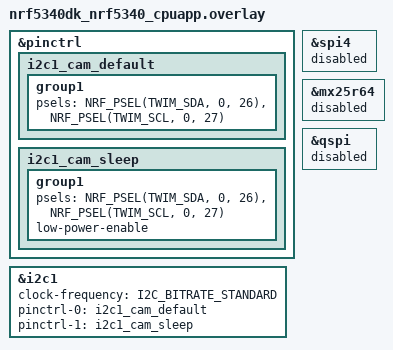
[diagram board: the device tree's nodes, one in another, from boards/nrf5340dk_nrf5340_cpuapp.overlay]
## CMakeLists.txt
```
cmake_minimum_required(VERSION 3.20.0)

find_package(Zephyr REQUIRED HINTS $ENV{ZEPHYR_BASE})
project(vuebuds_nrf5340)

# Compile-time choices, same names and values as fw/Makefile. tools/dk5340.py passes them as
# -Dfw_nrf5340_<var>=... (sysbuild hands image-prefixed variables to this image only).
#   CAM_MODE          QVGA (default), QQVGA or VGA (HM0360 only)
#   CAM_TEST_PATTERN  OFF (default), COLOR_BAR or WALKING_1
#   CAM_APP           STREAM (default) or MONITOR
#   EXTRA_DEFINES     extra defines, ';'-separated (like fw/'s CFLAGS=-DXXX)
#   CAM_BOARD         DK (default) or V3_L / V3_R: the V3 board (balsamic3, hub #83), with
#                     boards/balsamic3.overlay passed as EXTRA_DTC_OVERLAY_FILE (dk5340.py)
foreach(var CAM_MODE CAM_TEST_PATTERN CAM_APP EXTRA_DEFINES CAM_BOARD)
  zephyr_get(${var} SYSBUILD LOCAL)
endforeach()
if(NOT CAM_MODE)
  set(CAM_MODE QVGA)
endif()
if(NOT CAM_TEST_PATTERN)
  set(CAM_TEST_PATTERN OFF)
endif()
if(NOT CAM_APP)
  set(CAM_APP STREAM)
endif()
if(NOT CAM_BOARD)
  set(CAM_BOARD DK)
endif()
message(STATUS "vuebuds: CAM_MODE=${CAM_MODE} CAM_TEST_PATTERN=${CAM_TEST_PATTERN} CAM_APP=${CAM_APP} CAM_BOARD=${CAM_BOARD} EXTRA_DEFINES=${EXTRA_DEFINES}")

set(FW ${CMAKE_CURRENT_SOURCE_DIR}/../fw)

target_compile_definitions(app PRIVATE
  CAMERA_MODE=CAMERA_MODE_${CAM_MODE}
  CAM_MODE_${CAM_MODE}  # for #ifdef: CAMERA_MODE_* are enum values, invisible to #if
  CAMERA_TEST_PATTERN=CAMERA_TEST_PATTERN_${CAM_TEST_PATTERN}
  ${EXTRA_DEFINES}
)
if(CAM_BOARD MATCHES "^V3_([LR])$")
  target_compile_definitions(app PRIVATE BOARD_V3 BOARD_SIDE="${CMAKE_MATCH_1}")
elseif(NOT CAM_BOARD STREQUAL "DK")
  message(FATAL_ERROR "CAM_BOARD must be DK, V3_L or V3_R, not ${CAM_BOARD}")
endif()
if(CAM_APP STREQUAL "MONITOR")
  target_compile_definitions(app PRIVATE CAMERA_APP_MONITOR)
endif()

# Sensor drivers and register tables are shared with fw/ (not copied). They see the
# nRF5 SDK headers they include (i2c.h, timers.h, nrf_log.h, ...) through src/compat.
target_include_directories(app PRIVATE
  src
  src/compat
  src/capture
  ${FW}/sensors
  ${FW}/sensors/hm01b0/include
  ${FW}/sensors/hm0360/include
)
target_sources(app PRIVATE
  ${FW}/sensors/camera_sensor.c
  ${FW}/sensors/hm01b0/hm01b0_mode_info.c
  ${FW}/sensors/hm01b0/hm01b0_modes.c
  ${FW}/sensors/hm01b0/hm01b0_reg.c
  ${FW}/sensors/hm01b0/hm01b0_sensor.c
  ${FW}/sensors/hm0360/hm0360_mode_info.c
  ${FW}/sensors/hm0360/hm0360_modes.c
  ${FW}/sensors/hm0360/hm0360_reg.c
  ${FW}/sensors/hm0360/hm0360_sensor.c
)
file(GLOB APP_SOURCES src/*.c src/compat/*.c src/capture/*.c)
target_sources(app PRIVATE ${APP_SOURCES})

# JPEG / PNG encoders (lib/README.md): src/codec_jpeg.c / codec_png.c include the .inl files;
# PNGenc's zlib subset is built here, warnings off for this third-party code.
target_include_directories(app PRIVATE lib/jpegenc lib/pngenc)
set(ZLIB_SOURCES lib/pngenc/adler32.c lib/pngenc/crc32.c lib/pngenc/deflate.c lib/pngenc/trees.c lib/pngenc/zutil.c)
target_sources(app PRIVATE ${ZLIB_SOURCES})
# -O2 (Zephyr builds -Os): measured faster encodes, see DEVLOG 10-11.
set_source_files_properties(${ZLIB_SOURCES} src/codec_jpeg.c src/codec_png.c PROPERTIES COMPILE_OPTIONS "-w;-O2")
```

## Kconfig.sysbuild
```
source "share/sysbuild/Kconfig"

# Network core runs Nordic's ipc_radio image as the BLE controller (HCI over IPC).
config NRF_DEFAULT_IPC_RADIO
	default y

config NETCORE_IPC_RADIO_BT_HCI_IPC
	default y
```

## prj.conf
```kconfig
# Logs: printk to RTT (same channel as fw/'s NRF_LOG RTT backend), no UART console.
CONFIG_CONSOLE=y
CONFIG_PRINTK=y
CONFIG_USE_SEGGER_RTT=y
CONFIG_RTT_CONSOLE=y
CONFIG_UART_CONSOLE=n
CONFIG_SERIAL=n
CONFIG_SEGGER_RTT_BUFFER_SIZE_UP=4096

CONFIG_GPIO=y
CONFIG_I2C=y

CONFIG_MAIN_STACK_SIZE=4096
CONFIG_SYSTEM_WORKQUEUE_STACK_SIZE=2048

# BLE peripheral "mustard": same service, characteristics and packet format as fw/
# (host/protocol.py). The controller runs on the network core (sysbuild/ipc_radio).
CONFIG_BT=y
CONFIG_BT_PERIPHERAL=y
CONFIG_BT_GATT_CLIENT=y
CONFIG_BT_DEVICE_NAME="mustard"
CONFIG_BT_MAX_CONN=1
# Data length 251 like fw/ (NRF_SDH_BLE_GAP_DATA_LENGTH). ATT MTU 498 (fw/: 247; user 10-11):
# one 495-byte notification fills exactly two 251-byte link-layer packets (498 + 4 L2CAP = 502),
# half the notifications for the receiver to process (bridge: 1.38 -> 1.56 fps QVGA).
# The MTU is the smaller of the two sides' (Windows / the bridge accept 498).
CONFIG_BT_L2CAP_TX_MTU=498
CONFIG_BT_BUF_ACL_RX_SIZE=502
CONFIG_BT_BUF_ACL_TX_SIZE=251
CONFIG_BT_BUF_ACL_TX_COUNT=10
CONFIG_BT_BUF_EVT_RX_COUNT=11
CONFIG_BT_ATT_TX_COUNT=10
CONFIG_BT_CONN_TX_MAX=10
CONFIG_BT_USER_DATA_LEN_UPDATE=y
# fw/'s nrf_ble_gatt starts the data length update (251) after connecting.
CONFIG_BT_AUTO_DATA_LEN_UPDATE=y
# fw/ only answers PHY update requests (BLE_GAP_PHY_AUTO), it does not start one.
CONFIG_BT_AUTO_PHY_UPDATE=n
CONFIG_BT_USER_PHY_UPDATE=y
# Preferred connection parameters 7.5-15 ms, latency 0, timeout 4 s (fw/main.h), requested
# 5 s after connecting like FIRST_CONN_PARAMS_UPDATE_DELAY.
CONFIG_BT_GAP_AUTO_UPDATE_CONN_PARAMS=y
CONFIG_BT_PERIPHERAL_PREF_MIN_INT=6
CONFIG_BT_PERIPHERAL_PREF_MAX_INT=12
CONFIG_BT_PERIPHERAL_PREF_LATENCY=0
CONFIG_BT_PERIPHERAL_PREF_TIMEOUT=400
CONFIG_BT_CONN_PARAM_UPDATE_TIMEOUT=5000
CONFIG_REBOOT=y
# Time sync (src/timesync.c): connection anchor point reports from the controller (HCI VS event).
CONFIG_BT_HCI_VS_EVT_USER=y

# The frame pool takes all RAM after the image (src/capture/frame_pool.c); libc malloc would
# otherwise claim the same region as its arena. Nothing calls malloc.
CONFIG_COMMON_LIBC_MALLOC=n

# PSRAM on QSPI (src/psram.c): the nrfx driver only, no Zephyr flash driver.
CONFIG_NRFX_QSPI=y

# CRC32 for the PSRAM ring read-back check (src/ring.c, hub #26)
CONFIG_CRC=y
```

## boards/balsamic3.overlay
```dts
/*
 * balsamic3 (V3 board, hub #83): added on top of nrf5340dk_nrf5340_cpuapp.overlay by
 * tools/dk5340.py --board V3L / V3R (-Dfw_nrf5340_EXTRA_DTC_OVERLAY_FILE). Pins are the same as
 * on the DK (kicad-agent-flow boards/balsamic3/board.yaml, hub INTERFACES G): camera, I2C on
 * P0.26 / P0.27 (PMIC MAX77650 at 0x48, camera at 0x24) and the PSRAM on the QSPI pins. Only the
 * ISP2053 module differs, as in fw_v3_test/boards (verified on V3 2026-10):
 * - 32.768 kHz crystal: load capacitors are inside the module; ISP2053 DS R11 p.8 says
 *   XOSC32KI.INTCAP must select "External" (the DK uses internal 7 pF).
 * - Supply: VDD and VDDH tied to +1V8 (normal mode, DCCH open), so the VDDH regulator is unused;
 *   the module integrates the DC/DC inductors.
 * No buttons or LEDs are used (the firmware never used the DK's either). FSIN is not connected
 * on V3 (P1.11 free); the firmware does not drive it outside HW_TEST.
 */
&lfxo {
	load-capacitors = "external";
	/delete-property/ load-capacitance-picofarad;
};

&vregh {
	status = "disabled";
};
```

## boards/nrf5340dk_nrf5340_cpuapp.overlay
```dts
/*
 * Camera wiring on the nRF5340 DK (Obsidian note "nrf5340迁移" §2, src/pins.h).
 * Camera I2C on TWIM1 at P0.26 SDA / P0.27 SCL, 100 kHz like fw/. The DK's default
 * i2c1 pins (P1.02 / P1.03) are the camera PCLK / D0 here.
 * SPIS2 (camera data), TIMER0-2, EGU0 and DPPI channels 16-24 are used by the
 * application at register level (src/capture), so their nodes stay disabled.
 */
&pinctrl {
	i2c1_cam_default: i2c1_cam_default {
		group1 {
			psels = <NRF_PSEL(TWIM_SDA, 0, 26)>,
				<NRF_PSEL(TWIM_SCL, 0, 27)>;
		};
	};

	i2c1_cam_sleep: i2c1_cam_sleep {
		group1 {
			psels = <NRF_PSEL(TWIM_SDA, 0, 26)>,
				<NRF_PSEL(TWIM_SCL, 0, 27)>;
			low-power-enable;
		};
	};
};

&i2c1 {
	status = "okay";
	clock-frequency = <I2C_BITRATE_STANDARD>;
	pinctrl-0 = <&i2c1_cam_default>;
	pinctrl-1 = <&i2c1_cam_sleep>;
	pinctrl-names = "default", "sleep";
};

/* Arduino SPI (P1.13-P1.15): not used. */
&spi4 {
	status = "disabled";
};

/*
 * QSPI (P0.13-P0.18): the PSRAM (src/psram.c, nrfx_qspi at register level). The onboard
 * MX25R64 flash is cut off on our DKs (SB10-SB15 open, SB20-SB25 shorted), so no flash driver.
 */
&mx25r64 {
	status = "disabled";
};

&qspi {
	status = "disabled";
};
```

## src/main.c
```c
/*
 * nRF5340 DK port of fw/main.c: camera + BLE streaming (CAM_APP=STREAM, the default; it
 * also takes single pictures on 0xB2, snapshot.h) or Monitor (CAM_APP=MONITOR). The main thread runs the same event loop as fw/; it sleeps in
 * eventQueueWait() instead of nrf_pwr_mgmt_run(), and sends a frame in one call
 * (imageSend / bleSendImage return once every packet is queued) instead of polling bleService().
 * The VueBuds board's PMU, IMU, buttons, LEDs and CLI are not ported.
 */
#include <zephyr/kernel.h>
#include <zephyr/sys/reboot.h>
#ifdef CPU_128MHZ
#include <nrfx_clock.h>
#endif

#include "nrf_log.h"
#include "event.h"
#include "camera.h"
#include "monitor.h"
#include "snapshot.h"
#include "ble.h"
#include "image.h"
#include "timesync.h"
#include "ringcmd.h"
#include "i2c.h"
#include "psram.h"
#include "timers.h"
#ifdef BOARD_V3
#include "pmic.h"
#endif

#ifdef CAPTURE_STRESS_US
extern void stressTestStart(void);
#endif

// Stream builds take either a continuous stream (0xB1) or single / timed pictures (0xB2 / 0xB8) per boot.
static bool streaming;

static void processEvent(event_t event)
{
  switch (event) {
    case EVENT_BLE_DATA_STREAM_START:
      NRF_LOG_RAW_INFO("%08d [ble] stream start\n", systemTimeGetMs());
      break;

    case EVENT_BLE_DATA_STREAM_STOP:
    case EVENT_BLE_DISCONNECTED:
      sys_reboot(SYS_REBOOT_COLD);  // fw/: NVIC_SystemReset()
      break;

    case EVENT_CAMERA_STREAM_START:
#ifdef CAMERA_APP_MONITOR
      NRF_LOG_RAW_INFO("%08d [main] Monitor build: BLE streaming is disabled\n", systemTimeGetMs());
      break;
#endif
      if (snapshotActive() && !snapshotHandOver()) {
        // 0xB1 after 0xB2 / 0xB8 only once those are stopped (0xB8 0) and idle (INTERFACES C2).
        NRF_LOG_RAW_INFO("%08d [main] taking pictures (0xB2 / 0xB8): stream start ignored\n", systemTimeGetMs());
        break;
      }
      streaming = true;
      cameraInit();
      cameraStartStream();
#ifdef CAPTURE_STRESS_US
      stressTestStart();
#endif
      break;

    case EVENT_CAMERA_SNAPSHOT:
#ifdef CAMERA_APP_MONITOR
      NRF_LOG_RAW_INFO("%08d [main] Monitor build: single pictures are disabled\n", systemTimeGetMs());
      break;
#endif
      if (streaming) {
        NRF_LOG_RAW_INFO("%08d [main] streaming (0xB1): picture request ignored\n", systemTimeGetMs());
        break;
      }
      snapshotRequest();
      break;

    case EVENT_CAMERA_CAPTURE_DONE: {
#ifdef CAMERA_APP_MONITOR
      monitorFrameDone();
      break;
#endif
      if (snapshotActive()) {
        snapshotFrameDone();
        break;
      }
      NRF_LOG_RAW_INFO("%08d [cam] EVENT_CAMERA_CAPTURE_DONE\n", systemTimeGetMs());
      camera_frame_t frame;
      if (cameraGetFrame(&frame)) {
        imagePrepare(&frame);
        imageSend(&frame);
      }
      // Sent (or a bad frame, not sent): capture the next one.
      eventQueuePush(EVENT_CAMERA_READY_NEXT_FRAME);
      break;
    }

    case EVENT_CAMERA_READY_NEXT_FRAME:
      NRF_LOG_RAW_INFO("%08d [cam] EVENT_CAMERA_READY_NEXT_FRAME\n", systemTimeGetMs());
      cameraReadyNextFrame();
      break;

#ifdef CAMERA_APP_MONITOR
    case EVENT_MONITOR_START:
      monitorStart();
      break;

    case EVENT_MONITOR_WAKE:
      monitorWake();
      break;

    case EVENT_CAMERA_ASLEEP:
      monitorAsleep();
      break;
#else
    case EVENT_CAMERA_ASLEEP:
      snapshotAsleep();
      break;

    case EVENT_CAMERA_TIMED:
      snapshotTimedTick();
      break;

    case EVENT_CAMERA_RING_DUE:
      snapshotRingDue();
      break;
#endif

    case EVENT_BLE_COMMAND: {
      ble_command_t cmd;
      while (bleNextCommand(&cmd)) {
        if (cmd.data[0] == TIMESYNC_CMD_REFERENCE || cmd.data[0] == TIMESYNC_CMD_SNAPSHOT_AT) {
          uint64_t at;
          bool timed = timesyncCommand(&cmd, &at);
          (void)timed;  // Monitor builds take no pictures
#ifndef CAMERA_APP_MONITOR
          if (cmd.data[0] == TIMESYNC_CMD_SNAPSHOT_AT && !streaming) {
            if (timed) {
              snapshotRequestAt(at);
            } else {
              snapshotRequest();  // no time reference yet: now, like 0xB2
            }
          }
#endif
          continue;
        }
#ifndef CAMERA_APP_MONITOR
        if (cmd.data[0] == SNAPSHOT_CMD_TIMED) {
          if (streaming) {
            NRF_LOG_RAW_INFO("%08d [main] streaming (0xB1): timed capture / ring ignored\n", systemTimeGetMs());
          } else {
            ringcmdCommand(&cmd);  // 0xB8 0 / 1 / 2 (snapshot.h, ringcmd.h)
          }
          continue;
        }
        if (cmd.data[0] == RINGCMD_STATUS || cmd.data[0] == RINGCMD_FETCH) {
          ringcmdCommand(&cmd);  // also after a hand-over to the stream: the frames stay
          continue;
        }
#endif
        imageCommand(&cmd);
#ifndef CAMERA_APP_MONITOR
        if (cmd.data[0] == IMAGE_CMD_SET_EXPOSURE) {
          snapshotExposureChanged();
        } else if (cmd.data[0] == IMAGE_CMD_CODEC_BENCH && !streaming) {
          snapshotRequest();  // the bench picture (while streaming: the next streamed frame)
        }
#endif
      }
      break;
    }

    case EVENT_PSRAM_CHECK:
      psramCheckFinish();
#ifndef CAMERA_APP_MONITOR
      ringcmdInit();
#endif
      break;

    default:
      NRF_LOG_RAW_INFO("%08d [main] unhandled event:%d\n", systemTimeGetMs(), event);
      break;
  }
}

static void psramCheckDue(struct k_timer *t)
{
  eventQueuePush(EVENT_PSRAM_CHECK);
}
static K_TIMER_DEFINE(psramCheckTimer, psramCheckDue, NULL);

int main(void)
{
#ifdef BOARD_V3
  // V3 board (hub #83): camera AVDD from 3.3 V (PMIC power-up default) to 2.8 V before anything
  // else; the camera stays in reset (XSHUTDN pull-down) until then.
  bool pmicOk = pmicInit();
#endif
#ifdef CPU_128MHZ
  // Experiment (10-11): the application core runs at 64 MHz by default (HFCLK / 2); 128 MHz as
  // in nrf/samples/bluetooth/nrf_auraconfig, for the JPEG / PNG encoders.
  int divErr = nrfx_clock_divider_set(NRF_CLOCK_DOMAIN_HFCLK, NRF_CLOCK_HFCLK_DIV_1);
  SystemCoreClockUpdate();
  NRF_LOG_RAW_INFO("[mustard] CPU %u MHz (%d)\n", SystemCoreClock / 1000000, divErr);
#endif
#ifdef BOARD_V3
  NRF_LOG_RAW_INFO("%08d [mustard] booting... (nRF5340, V3 board %s, PMIC %s)\n", systemTimeGetMs(), BOARD_SIDE,
                   pmicOk ? "ok" : "NOT OK");
#else
  NRF_LOG_RAW_INFO("%08d [mustard] booting... (nRF5340)\n", systemTimeGetMs());
#endif
  i2cInit();
#ifdef HW_TEST
  extern void hwTestRun(void);
  hwTestRun();  // hardware check only (src/hw_test.c): no BLE, no camera application
  for (;;) {
    k_sleep(K_FOREVER);
  }
#endif
  // PSRAM boot check (psram.h): write now, read back PSRAM_CHECK_WAIT_MS later without holding
  // up BLE; a picture compressed before then waits for it (image.c).
  psramCheckStart();
  if (psramState() == PSRAM_STATE_WAITING) {
    k_timer_start(&psramCheckTimer, K_MSEC(PSRAM_CHECK_WAIT_MS), K_NO_WAIT);
  } else {
    eventQueuePush(EVENT_PSRAM_CHECK);  // failed at once: set up the ring (in RAM) now
  }
  bleInit();
#ifdef BOARD_V3
  cameraProbe();  // V3 boards start without a camera module (hub #83): say so in the log
#endif
  NRF_LOG_RAW_INFO("%08d [mustard] booted\n", systemTimeGetMs());

#ifdef CAMERA_APP_MONITOR
  eventQueuePush(EVENT_MONITOR_START);
#endif

  for (;;) {
    processEvent(eventQueueWait());
  }
  return 0;
}
```

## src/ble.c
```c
/*
 * BLE peripheral "mustard" on Zephyr, same protocol as fw/ble_manager.c + fw/ble_cus.c:
 *   service 47ea1400-a0e4-554e-5282-0afcd3246970
 *   data    ...1402  notify: [seq, flags, payload...], flags bit0 = start of frame; fw/'s
 *                   start-of-frame payload begins with width, height (uint16 LE each); here
 *                   flags bit1 is set and it begins with ble_frame_header_t (v2, ble.h)
 *   control ...1403  write 0xB1: start the camera stream (read / notify, 1 byte)
 *                    write 0xB2: take one picture (not in fw/; see snapshot.h)
 *                    longer writes (0xB3 ...): commands for the main thread (image.c, ringcmd.c)
 *   data packets with flags bit2 are M2 replies [seq, 0x04, type, ...] (ringcmd.h)
 * Like fw/, turning data notifications off or disconnecting reboots the chip.
 */
#include <string.h>

#include <zephyr/kernel.h>
#include <zephyr/sys/util.h>
#include <zephyr/bluetooth/bluetooth.h>
#include <zephyr/bluetooth/conn.h>
#include <zephyr/bluetooth/gatt.h>
#include <zephyr/bluetooth/uuid.h>

#include "nrf_log.h"
#include "event.h"
#include "timers.h"
#include "ble.h"
#include "timesync.h"

#define ADV_INTERVAL 300  // 187.5 ms in 0.625 ms units, as fw/main.h APP_ADV_INTERVAL
#define PACKET_FLAG_START_OF_FRAME 0x01
#define PACKET_FLAG_HEADER_V2 0x02
#define PACKET_FLAG_REPLY 0x04  // M2 reply packet (R_STATUS ..., ble.h)
#define CMD_STREAM_START 0xB1
#define CMD_STREAM_STOP 0xB0
#define CMD_SNAPSHOT 0xB2
#define NOTIFY_IN_FLIGHT CONFIG_BT_ATT_TX_COUNT
#define NOTIFY_WAIT_MS 2000  // no notification completed for this long: give up the frame

#define UUID_BASE(x) BT_UUID_128_ENCODE(0x47ea0000 | (x), 0xa0e4, 0x554e, 0x5282, 0x0afcd3246970)
static const struct bt_uuid_128 serviceUuid = BT_UUID_INIT_128(UUID_BASE(0x1400));
static const struct bt_uuid_128 dataUuid = BT_UUID_INIT_128(UUID_BASE(0x1402));
static const struct bt_uuid_128 controlUuid = BT_UUID_INIT_128(UUID_BASE(0x1403));

static struct bt_conn *currentConn;
static uint8_t controlValue;
static uint8_t sequenceNumber;
static uint8_t packet[CONFIG_BT_L2CAP_TX_MTU];
K_SEM_DEFINE(notifySlots, NOTIFY_IN_FLIGHT, NOTIFY_IN_FLIGHT);
BUILD_ASSERT(sizeof(ble_frame_header_t) == 22, "frame header v2 is 22 bytes (host/protocol.py HEADER_V2)");
K_MSGQ_DEFINE(commandQueue, sizeof(ble_command_t), 8, 4);
// Data notifications come from the main thread (stream, pictures) and the ring sender thread
// (ringcmd.c): one frame's packets go out back to back, replies between frames (recursive).
K_MUTEX_DEFINE(txLock);

static void dataCccChanged(const struct bt_gatt_attr *attr, uint16_t value)
{
  if (value & BT_GATT_CCC_NOTIFY) {
    eventQueuePush(EVENT_BLE_DATA_STREAM_START);
  } else {
    eventQueuePush(EVENT_BLE_DATA_STREAM_STOP);
  }
}

static ssize_t controlRead(struct bt_conn *conn, const struct bt_gatt_attr *attr, void *buf, uint16_t len,
                           uint16_t offset)
{
  return bt_gatt_attr_read(conn, attr, buf, len, offset, &controlValue, sizeof(controlValue));
}

static ssize_t controlWrite(struct bt_conn *conn, const struct bt_gatt_attr *attr, const void *buf, uint16_t len,
                            uint16_t offset, uint8_t flags)
{
  if (offset != 0 || len < 1 || len > BLE_COMMAND_MAX) {
    return BT_GATT_ERR(BT_ATT_ERR_INVALID_ATTRIBUTE_LEN);
  }
  uint8_t cmd = *(const uint8_t *)buf;
  NRF_LOG_INFO("writing to 1403 0x%02x (%u bytes)", cmd, len);
  if (len > 1 || (cmd != CMD_STREAM_START && cmd != CMD_SNAPSHOT && cmd != CMD_STREAM_STOP)) {
    ble_command_t c = {.len = len};
    memcpy(c.data, buf, len);
    if (k_msgq_put(&commandQueue, &c, K_NO_WAIT) == 0) {
      eventQueuePush(EVENT_BLE_COMMAND);
    }
  } else if (cmd == CMD_STREAM_START) {
    eventQueuePush(EVENT_CAMERA_STREAM_START);
  } else if (cmd == CMD_SNAPSHOT) {
    eventQueuePush(EVENT_CAMERA_SNAPSHOT);
  }
  // 0xB0 (stream stop) did nothing in fw/ either; the audio / timesync commands are not ported.
  return len;
}

static void controlCccChanged(const struct bt_gatt_attr *attr, uint16_t value) {}

BT_GATT_SERVICE_DEFINE(mustardService,
  BT_GATT_PRIMARY_SERVICE(&serviceUuid),
  BT_GATT_CHARACTERISTIC(&dataUuid.uuid, BT_GATT_CHRC_NOTIFY, BT_GATT_PERM_NONE, NULL, NULL, NULL),
  BT_GATT_CCC(dataCccChanged, BT_GATT_PERM_READ | BT_GATT_PERM_WRITE),
  BT_GATT_CHARACTERISTIC(&controlUuid.uuid,
                         BT_GATT_CHRC_READ | BT_GATT_CHRC_WRITE_WITHOUT_RESP | BT_GATT_CHRC_NOTIFY,
                         BT_GATT_PERM_READ | BT_GATT_PERM_WRITE, controlRead, controlWrite, NULL),
  BT_GATT_CCC(controlCccChanged, BT_GATT_PERM_READ | BT_GATT_PERM_WRITE),
);

#define DATA_ATTR (&mustardService.attrs[2])
#define CONTROL_ATTR (&mustardService.attrs[5])

static const struct bt_data advData[] = {
  BT_DATA_BYTES(BT_DATA_FLAGS, (BT_LE_AD_GENERAL | BT_LE_AD_NO_BREDR)),
  BT_DATA(BT_DATA_NAME_COMPLETE, CONFIG_BT_DEVICE_NAME, sizeof(CONFIG_BT_DEVICE_NAME) - 1),
  BT_DATA_BYTES(BT_DATA_UUID128_ALL, UUID_BASE(0x1400)),
};

static void mtuExchanged(struct bt_conn *conn, uint8_t err, struct bt_gatt_exchange_params *params)
{
  NRF_LOG_INFO("ATT MTU exchange %s, MTU %u", err ? "failed" : "done", bt_gatt_get_mtu(conn));
}
static struct bt_gatt_exchange_params mtuParams = {.func = mtuExchanged};

static void connected(struct bt_conn *conn, uint8_t err)
{
  if (err) {
    NRF_LOG_RAW_INFO("%08d [ble] connection failed (0x%02x)\n", systemTimeGetMs(), err);
    return;
  }
  currentConn = bt_conn_ref(conn);
  NRF_LOG_RAW_INFO("%08d [ble] connected\n", systemTimeGetMs());
  bt_gatt_exchange_mtu(conn, &mtuParams);  // like nrf_ble_gatt: ask for the largest MTU (498, prj.conf)
}

static void disconnected(struct bt_conn *conn, uint8_t reason)
{
  NRF_LOG_RAW_INFO("%08d [ble] disconnected (0x%02x)\n", systemTimeGetMs(), reason);
  if (currentConn) {
    bt_conn_unref(currentConn);
    currentConn = NULL;
  }
  eventQueuePush(EVENT_BLE_DISCONNECTED);
}

static void controlNotify(struct k_work *work)
{
  struct bt_conn *conn = currentConn;
  if (conn && bt_gatt_is_subscribed(conn, CONTROL_ATTR, BT_GATT_CCC_NOTIFY)) {
    bt_gatt_notify(conn, CONTROL_ATTR, &controlValue, sizeof(controlValue));
  }
}
static K_WORK_DEFINE(controlNotifyWork, controlNotify);

static void paramsUpdated(struct bt_conn *conn, uint16_t interval, uint16_t latency, uint16_t timeout)
{
  // Same text as fw/ (min, max in ms; host/ble_bench.py parses it). Zephyr reports the one in use.
  NRF_LOG_INFO("Connection interval updated: %d, %d", (5 * interval) / 4, (5 * interval) / 4);
  // fw/ writes 0xFF to the control characteristic here (notified if enabled). Notified from
  // the system work queue: this callback runs on the BT RX thread, which must not block on a
  // TX buffer while a frame fills the queue.
  controlValue = 0xFF;
  k_work_submit(&controlNotifyWork);
}

static void dataLenUpdated(struct bt_conn *conn, struct bt_conn_le_data_len_info *info)
{
  NRF_LOG_INFO("Data length updated to %u bytes.", info->tx_max_len);
}

static void phyUpdated(struct bt_conn *conn, struct bt_conn_le_phy_info *info)
{
  NRF_LOG_INFO("PHY updated: tx %u, rx %u", info->tx_phy, info->rx_phy);
}

BT_CONN_CB_DEFINE(connCallbacks) = {
  .connected = connected,
  .disconnected = disconnected,
  .le_param_updated = paramsUpdated,
  .le_data_len_updated = dataLenUpdated,
  .le_phy_updated = phyUpdated,
};

void bleInit(void)
{
  int err = bt_enable(NULL);
  if (err) {
    NRF_LOG_RAW_INFO("[ble] bt_enable failed (%d)\n", err);
    return;
  }
  timesyncBleReady();
  err = bt_le_adv_start(BT_LE_ADV_PARAM(BT_LE_ADV_OPT_CONN, ADV_INTERVAL, ADV_INTERVAL, NULL), advData,
                        ARRAY_SIZE(advData), NULL, 0);
  if (err) {
    NRF_LOG_RAW_INFO("[ble] advertising failed (%d)\n", err);
    return;
  }
  bt_addr_le_t addr;
  size_t count = 1;
  bt_id_get(&addr, &count);
  char str[BT_ADDR_LE_STR_LEN];
  bt_addr_le_to_str(&addr, str, sizeof(str));
  NRF_LOG_RAW_INFO("%08d [ble] address -> %s\n", systemTimeGetMs(), str);
  NRF_LOG_RAW_INFO("%08d [ble] advertising\n", systemTimeGetMs());
}

static bool sendImage(const ble_frame_header_t *header, ble_reader_t read, void *ctx);

static void notifyDone(struct bt_conn *conn, void *user_data)
{
  k_sem_give(&notifySlots);
}

// Queue one packet; waits while NOTIFY_IN_FLIGHT notifications are in the stack.
static bool sendPacket(uint16_t length)
{
  if (k_sem_take(&notifySlots, K_MSEC(NOTIFY_WAIT_MS)) != 0) {
    NRF_LOG_RAW_INFO("%08d [ble] no notification completed in %d ms, frame dropped\n", systemTimeGetMs(),
                     NOTIFY_WAIT_MS);
    return false;
  }
  if (currentConn == NULL) {
    k_sem_give(&notifySlots);
    return false;
  }
  struct bt_gatt_notify_params params = {
    .attr = DATA_ATTR,
    .data = packet,
    .len = length,
    .func = notifyDone,
  };
  int err = bt_gatt_notify_cb(currentConn, &params);
  if (err) {
    k_sem_give(&notifySlots);
    NRF_LOG_ERROR("ble transmit failed: %d", err);
    return false;
  }
  return true;
}

bool bleNextCommand(ble_command_t *cmd)
{
  return k_msgq_get(&commandQueue, cmd, K_NO_WAIT) == 0;
}

void bleLock(void)
{
  k_mutex_lock(&txLock, K_FOREVER);
}

void bleUnlock(void)
{
  k_mutex_unlock(&txLock);
}

bool bleSendReply(uint8_t type, const void *data, uint16_t len)
{
  bleLock();
  bool ok = false;
  if (currentConn != NULL && 3u + len <= MIN(bt_gatt_get_mtu(currentConn) - 3, sizeof(packet))) {
    packet[0] = sequenceNumber;
    packet[1] = PACKET_FLAG_REPLY;
    packet[2] = type;
    memcpy(&packet[3], data, len);
    ok = sendPacket(3 + len);
    if (ok) {
      sequenceNumber++;
    }
  }
  bleUnlock();
  return ok;
}

bool bleSendImage(const ble_frame_header_t *header, ble_reader_t read, void *ctx)
{
  bleLock();
  bool ok = sendImage(header, read, ctx);
  bleUnlock();
  return ok;
}

static bool sendImage(const ble_frame_header_t *header, ble_reader_t read, void *ctx)
{
  if (currentConn == NULL) {
    return false;
  }
  uint16_t maxPayload = MIN(bt_gatt_get_mtu(currentConn) - 3, sizeof(packet));
  bool startOfFrame = true;
  uint32_t offset = 0;

  while (startOfFrame || offset < header->length) {
    uint16_t length = 0;
    packet[length++] = sequenceNumber;
    packet[length++] = startOfFrame ? (PACKET_FLAG_START_OF_FRAME | PACKET_FLAG_HEADER_V2) : 0;
    if (startOfFrame) {
      memcpy(&packet[length], header, sizeof(*header));
      length += sizeof(*header);
    }
    while (length < maxPayload && offset < header->length) {
      size_t n = read(ctx, offset, &packet[length], MIN(maxPayload - length, header->length - offset));
      if (n == 0) {
        NRF_LOG_RAW_INFO("%08d [ble] image source failed at byte %u, frame dropped\n", systemTimeGetMs(), offset);
        return false;
      }
      length += n;
      offset += n;
    }
    if (!sendPacket(length)) {
      return false;  // disconnected (EVENT_BLE_DISCONNECTED follows) or stalled
    }
    startOfFrame = false;
    sequenceNumber++;
  }
  return true;
}
```

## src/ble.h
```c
/* BLE peripheral, same protocol as fw/ble_manager.c + ble_cus.c (see host/protocol.py). */
#ifndef BLE_H_
#define BLE_H_

#include <stdbool.h>
#include <stddef.h>
#include <stdint.h>

/*
 * Frame header v2 (2026-10-11, host/protocol.py): the start-of-frame packet has flags bit1 set
 * and its payload starts with this header instead of v1's width, height. Little endian.
 */
#define BLE_FORMAT_RAW  0  // 8-bit gray, width x height
#define BLE_FORMAT_PNG  1
#define BLE_FORMAT_JPEG 2

#define BLE_HEADER_COMMON_CLOCK    0x01  // capture_us is on the bridge's common clock (time sync)
#define BLE_HEADER_MANUAL_EXPOSURE 0x02
#define BLE_HEADER_SKIPPED         0x04  // 0xB8: at least one period was skipped before this picture
#define BLE_HEADER_FROM_RING       0x08  // M2: sent out of the ring buffer (after an R_FRAME reply)
#define BLE_HEADER_TIMED           0x10  // 0xB8: taken by the timed capture (not a 0xB2 request)

typedef struct __packed {
  uint16_t width;
  uint16_t height;
  uint8_t format;         // BLE_FORMAT_*
  uint8_t quality;        // JPEG quality, else 0
  uint32_t length;        // image bytes after the header (raw: width x height)
  uint32_t capture_us;    // FVLD rise of this frame (board clock unless BLE_HEADER_COMMON_CLOCK)
  uint16_t frame_id;      // frames sent since boot
  uint16_t integration;   // exposure registers read after the frame: 0x0202 / 0x0203 (rows)
  uint8_t analog_gain;    // 0x0205
  uint16_t digital_gain;  // 0x020E << 8 | 0x020F
  uint8_t flags;          // BLE_HEADER_*
} ble_frame_header_t;

/* Copies image bytes [offset, offset + n) to dst; returns the bytes copied (0: source failed). */
typedef size_t (*ble_reader_t)(void *ctx, uint32_t offset, uint8_t *dst, size_t n);

/* Multi-byte control commands (0xB3 ...), queued for the main thread (EVENT_BLE_COMMAND). */
#define BLE_COMMAND_MAX 24  // 0xB7: 1 + 8 + 2 + 8 bytes
typedef struct {
  uint8_t len;
  uint8_t data[BLE_COMMAND_MAX];
} ble_command_t;

void bleInit(void);  // starts advertising
// Sends header + header->length bytes from read() and returns when every packet is queued.
bool bleSendImage(const ble_frame_header_t *header, ble_reader_t read, void *ctx);
bool bleNextCommand(ble_command_t *cmd);  // false when the queue is empty
/* M2 reply packet [seq, flags 0x04, type, data...] (ringcmd.h); sent between frames. */
bool bleSendReply(uint8_t type, const void *data, uint16_t len);
/* Hold the data channel across several sends (an R_FRAME reply and its frame); recursive. */
void bleLock(void);
void bleUnlock(void);

#endif
```

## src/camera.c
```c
/*
 * nRF5340 port of fw/camera.c. Same flow and constants; app_timer -> k_timer, and
 * cameraDeInit / cameraEnableStandbyMode (power-off and button paths of the VueBuds board,
 * unused on the DK) are not ported.
 */
#include <stdbool.h>
#include <stdint.h>

#include <zephyr/kernel.h>

#include "nrf_log.h"
#include "nrf_delay.h"
#include "event.h"
#include "camera_sensor.h"
#include "capture.h"
#include "camera.h"
#include "pins.h"
#include "timers.h"
#include "i2c.h"
#include "timesync.h"

// Mode and test pattern are compile-time choices (no runtime switching).
#ifndef CAMERA_MODE
#define CAMERA_MODE CAMERA_MODE_QVGA
#endif
#ifndef CAMERA_TEST_PATTERN
#define CAMERA_TEST_PATTERN CAMERA_TEST_PATTERN_OFF
#endif

#define CAMERA_POR_DELAY_MS 100
#define CAMERA_XSHUTDOWN_LOW_MS 10
// Datasheet table 6.2: >= 200 us from reset release to XSLEEP, >= 10 us to the first I2C command.
// Measured: the ID reads back right away; detection polls anyway.
#define CAMERA_BOOT_DELAY_MS 1
#define CAMERA_DETECT_TIMEOUT_MS 1000
#define CAMERA_XSLEEP_SETTLE_US 100  // >= 10 us from XSLEEP high to I2C (datasheet table 6.2)
// Longest wait for a frame boundary. Right after a capture it is 36 blank lines away
// (QQVGA / QVGA 376 us lines: 13.5 ms; VGA 768 us lines: 27.6 ms); requested at another
// time it is up to two frames away (QVGA 2 x 103.8 ms, VGA 2 x 396 ms).
// After-frame timeout: fw/ waits 30 ms. A frame in which the HM0360's AE changed the gain
// has no FVLD low gap at its end at all (measured 10-07: 30 of 30 gain changes, 0 of 28
// unchanged frames), so that wait was always spent in full. 16 ms is just past the 13.5 ms
// boundary; XSLEEP low then does not delay the next wake (user choice B, 10-07).
#ifdef CAM_MODE_VGA  // from CMakeLists (CAMERA_MODE is an enum value, invisible to #if)
#define CAMERA_SLEEP_AFTER_FRAME_TIMEOUT_MS 30
#define CAMERA_SLEEP_ANYTIME_TIMEOUT_MS 850
#else
#define CAMERA_SLEEP_AFTER_FRAME_TIMEOUT_MS 16
#define CAMERA_SLEEP_ANYTIME_TIMEOUT_MS 250
#endif

static void applyPendingExposure(void);  // set before the sensor started (cameraSetExposure)

static bool cameraInitialized = false;
static uint8_t m_state = CAMERA_STATE_UNCHECKED;  // cameraState()
static const camera_sensor_t *sensor = NULL;
static camera_mode_info_t modeInfo;

/*
 * Reset the HM0360 through XSHUTDOWN with MCLK already running, so it always starts
 * from a clean state (it does not answer I2C if it powered up without MCLK), and keep
 * XSLEEP high. Both pins are unconnected on HM01B0 boards, where this does nothing.
 */
static void cameraHardwareReset(void)
{
  nrf_gpio_cfg_output(CAM_XSLEEP);
  nrf_gpio_pin_set(CAM_XSLEEP);
  nrf_gpio_cfg_output(CAM_XSHUTDOWN);
  nrf_gpio_pin_clear(CAM_XSHUTDOWN);
  delayMs(CAMERA_XSHUTDOWN_LOW_MS);
  nrf_gpio_pin_set(CAM_XSHUTDOWN);
  delayMs(CAMERA_BOOT_DELAY_MS);
}

void cameraInit(void)
{
  if (cameraInitialized) {
    NRF_LOG_INFO("[camera] already initialized, skipping");
    return;
  }

  // The sensor runs from our MCLK, including its I2C slave, so start it first.
  capture_mclk_init();
  delayMs(CAMERA_POR_DELAY_MS);
  cameraHardwareReset();

  if (camera_sensor_detect(&sensor, CAMERA_DETECT_TIMEOUT_MS) != NRF_SUCCESS) {
    m_state = CAMERA_STATE_MISSING;
    capture_mclk_enable(false);
    return;
  }
  m_state = CAMERA_STATE_PRESENT;

  if (sensor->get_mode_info(CAMERA_MODE, &modeInfo) != NRF_SUCCESS) {
    // e.g. VGA on an HM01B0 (no such mode): leave the camera off.
    NRF_LOG_RAW_INFO("[camera] %s has no %s mode, camera not started\n", sensor->name,
                     camera_mode_name(CAMERA_MODE));
    sensor = NULL;
    capture_mclk_enable(false);
    return;
  }
  ret_code_t err_code = sensor->init(CAMERA_MODE, CAMERA_TEST_PATTERN);
  if (err_code != NRF_SUCCESS) {
    NRF_LOG_RAW_INFO("[camera] %s init failed: 0x%x\n", sensor->name, err_code);
  }
  NRF_LOG_RAW_INFO("[camera] %s %s, test pattern %d, sent as %ux%u\n", sensor->name,
                   camera_mode_name(CAMERA_MODE), CAMERA_TEST_PATTERN,
                   modeInfo.standard.width, modeInfo.standard.height);
#ifdef CAMERA_REG_DUMP
  // hub #68 item 3: compare the two boards' sensors (ID, revision, AE settings), read after init.
  {
    static const uint16_t blocks[][2] = {{0x0000, 0x0003}, {0x0100, 0x0104}, {0x0202, 0x0205}, {0x020E, 0x020F},
                                         {0x2000, 0x203F}, {0x3024, 0x3030}};
    for (int b = 0; b < (int)ARRAY_SIZE(blocks); b++) {
      for (uint16_t r = blocks[b][0]; r <= blocks[b][1]; r += 8) {
        NRF_LOG_RAW_INFO("[regs] %04x:", r);
        for (uint16_t k = r; k < r + 8 && k <= blocks[b][1]; k++) {
          NRF_LOG_RAW_INFO(" %02x", i2cRead16(CAMERA_I2C_ADDR, k));
        }
        NRF_LOG_RAW_INFO("\n");
        k_msleep(5);  // RTT buffer is 512 B
      }
    }
  }
#endif

  capture_init(&modeInfo);

  // Clock gating: MCLK only runs while streaming.
  capture_mclk_enable(false);

  cameraInitialized = true;
}

void cameraStartStream(void)
{
  if (!cameraInitialized) {
    return;
  }
  capture_mclk_enable(true);
  capture_arm();
  sensor->stream_start();
  applyPendingExposure();
  NRF_LOG_RAW_INFO("%08d [cam] stream started\n", systemTimeGetMs());
}

void cameraReadyNextFrame(void)
{
  capture_arm();
}

bool cameraGetFrame(camera_frame_t *frame)
{
  if (!cameraInitialized) {
    return false;
  }

  const capture_stats_t *stats = capture_stats();
  NRF_LOG_RAW_INFO("%08d [cam] frame %u: %u us, dma", systemTimeGetMs(), stats->frame, stats->duration_us);
  for (uint8_t i = 0; i < stats->segments; i++) {
    NRF_LOG_RAW_INFO(" %u", stats->segment_bytes[i]);
  }
  NRF_LOG_RAW_INFO("%s%s\n", stats->overflow ? " OVERFLOW" : "", stats->ok ? "" : ", BAD, dropped");
  if (!stats->ok) {
    // Wrong byte count or overflow (a late CS edge shifted part of the frame): do not send it.
    return false;
  }

  frame->stride = modeInfo.transport_width;
  frame->width = modeInfo.standard.width;
  frame->height = modeInfo.standard.height;
  frame->pixels = capture_frame() + (uint32_t)modeInfo.standard.y * frame->stride + modeInfo.standard.x;
  return true;
}

#ifdef BOARD_V3
/*
 * V3 boot (hub #83): is a camera module plugged in? MCLK on, reset pulse, read the model ID and
 * revision quietly, then MCLK off and XSHUTDOWN low again (the module's reset state, 10 k
 * pull-down on the board), so cameraInit() later starts from the same state as on the DK.
 */
uint16_t cameraProbe(void)
{
  capture_mclk_init();
  delayMs(CAMERA_POR_DELAY_MS);
  cameraHardwareReset();
  uint8_t id[4] = {0};
  int err = 0;
  for (int i = 0; i < 4 && !err; i++) {
    err = i2cTryRead16(CAMERA_I2C_ADDR, (uint16_t)i, &id[i]);
  }
  capture_mclk_enable(false);
  nrf_gpio_pin_clear(CAM_XSHUTDOWN);
  uint16_t model = ((uint16_t)id[0] << 8) | id[1];
  if (err) {
    NRF_LOG_RAW_INFO("[camera] no camera: nothing answers at 0x%02x (%d); pictures and the ring stay off\n",
                     CAMERA_I2C_ADDR, err);
    m_state = CAMERA_STATE_MISSING;
    return 0;
  }
  m_state = CAMERA_STATE_PRESENT;
  NRF_LOG_RAW_INFO("[camera] found model 0x%04x, silicon revision 0x%02x (0x0003: 0x%02x)\n", model, id[2], id[3]);
  return model;
}
#endif

uint8_t cameraState(void)
{
  return m_state;
}

uint16_t cameraModelId(void)
{
  return (cameraInitialized && sensor != NULL) ? sensor->model_id : 0;
}

const char *cameraModeName(void)
{
  return camera_mode_name(CAMERA_MODE);
}

uint32_t cameraSlotCount(void)
{
  return cameraInitialized ? frame_pool_slot_count() : 0;
}

void cameraSensorStream(void)
{
  if (!cameraInitialized) {
    return;
  }
  capture_mclk_enable(true);
  sensor->stream_start();
  applyPendingExposure();
}

// HM0360 S2: MCLK runs whenever XSLEEP is high (datasheet: MCLK first, then XSLEEP).
static enum { CAMERA_AWAKE, CAMERA_FALLING_ASLEEP, CAMERA_ASLEEP } sleepState = CAMERA_AWAKE;
static uint32_t sleepTimeoutMs;
static uint64_t wakeAtUs;  // cameraWakeAt() armed for this local time (0: none)

// No frame boundary in time (seen on the first wake after the stream starts, when FVLD
// stays high from one frame to the next): sleep anyway, like PR #26's 30 ms timeout.
static volatile bool sleepTimedOut;
static void sleepTimeout(struct k_timer *timer)
{
  if (sleepState == CAMERA_FALLING_ASLEEP) {
    sleepTimedOut = true;
    capture_xsleep(false);
    NRF_LOG_RAW_INFO("%08d [cam] no frame boundary within %u ms, XSLEEP low anyway\n", systemTimeGetMs(),
                     sleepTimeoutMs);
    eventQueuePush(EVENT_CAMERA_ASLEEP);
  }
}
K_TIMER_DEFINE(sleepTimeoutTimer, sleepTimeout, NULL);

// Exposure: AE (the HM0360 table's AE_CTRL 0x1F) or fixed values with AE off (as OpenMV's
// set_auto_exposure: AE_CTRL bit0 off, then integration / gains, then COMMAND_UPDATE).
// Fixed values only hold while the sensor keeps streaming: waking from S2 meters the scene
// itself and the first frames ignore the registers (10-11: registers read back the fixed values,
// the picture stayed at the AE target; pre-meter off, Context A AE_CTRL, AE update off, writing
// 40 ms after the wake and skipping a frame changed nothing). snapshot.c therefore keeps the
// sensor awake while the exposure is manual.
#define HM0360_AE_CTRL 0x2000
#define HM0360_AE_CTRL_AUTO 0x1F    // hm0360_modes.c
#define HM0360_AE_CTRL_MANUAL 0x1E  // bit0 = AE enable (datasheet 10.13)
#define SENSOR_COMMAND_UPDATE 0x0104
static bool exposureManual;
static bool exposurePending;  // set while asleep: written right after the next wake
static camera_exposure_t exposureValues;

static bool sensorAwake(void)
{
  return cameraInitialized && sensor != NULL && sleepState == CAMERA_AWAKE && capture_mclk_running();
}

static void writeExposure(void)
{
  if (exposureManual) {
    i2cWrite16(CAMERA_I2C_ADDR, HM0360_AE_CTRL, HM0360_AE_CTRL_MANUAL);
    i2cWrite16(CAMERA_I2C_ADDR, 0x0202, exposureValues.integration >> 8);
    i2cWrite16(CAMERA_I2C_ADDR, 0x0203, exposureValues.integration & 0xFF);
    i2cWrite16(CAMERA_I2C_ADDR, 0x0205, exposureValues.analog_gain);
    i2cWrite16(CAMERA_I2C_ADDR, 0x020E, exposureValues.digital_gain >> 8);
    i2cWrite16(CAMERA_I2C_ADDR, 0x020F, exposureValues.digital_gain & 0xFF);
  } else {
    i2cWrite16(CAMERA_I2C_ADDR, HM0360_AE_CTRL, HM0360_AE_CTRL_AUTO);
  }
  // Latch the double-buffered registers; write-only, so no read-back check.
  i2cWrite16NoVerify(CAMERA_I2C_ADDR, SENSOR_COMMAND_UPDATE, 0x01);
  exposurePending = false;
}

bool cameraReadExposure(camera_exposure_t *exposure)
{
  if (!sensorAwake()) {
    return false;
  }
  exposure->integration = (i2cRead16(CAMERA_I2C_ADDR, 0x0202) << 8) | i2cRead16(CAMERA_I2C_ADDR, 0x0203);
  exposure->analog_gain = i2cRead16(CAMERA_I2C_ADDR, 0x0205);
  exposure->digital_gain = (i2cRead16(CAMERA_I2C_ADDR, 0x020E) << 8) | i2cRead16(CAMERA_I2C_ADDR, 0x020F);
  return true;
}

void cameraSetExposure(const camera_exposure_t *exposure)
{
  if (sensor != NULL && sensor->model_id != 0x0360) {
    NRF_LOG_RAW_INFO("[cam] manual exposure is HM0360 only\n");
    return;
  }
  exposureManual = exposure != NULL;
  if (exposure != NULL) {
    exposureValues = *exposure;
  }
  exposurePending = true;
  if (sensorAwake()) {
    writeExposure();
  }
  NRF_LOG_RAW_INFO("%08d [cam] exposure %s: integration %u, analog gain 0x%02x, digital gain 0x%04x%s\n",
                   systemTimeGetMs(), exposureManual ? "manual" : "auto", exposureValues.integration,
                   exposureValues.analog_gain, exposureValues.digital_gain,
                   exposurePending ? " (after the next wake)" : "");
}

static void applyPendingExposure(void)
{
  if (exposurePending && sensorAwake()) {
    writeExposure();
  }
}

bool cameraExposureManual(void)
{
  return exposureManual;
}

void cameraReapplyExposure(void)
{
  if (exposureManual && sensorAwake()) {
    writeExposure();
  }
}

void cameraWake(void)
{
  k_timer_stop(&sleepTimeoutTimer);
  wakeAtUs = 0;
  capture_mclk_enable(true);
  nrf_delay_us(CAMERA_XSLEEP_SETTLE_US);
  capture_xsleep(true);
  sleepState = CAMERA_AWAKE;
  if (exposurePending) {
    nrf_delay_us(CAMERA_XSLEEP_SETTLE_US);  // >= 10 us from XSLEEP high to I2C
    writeExposure();
  }
}

bool cameraWakeAt(uint64_t local_us)
{
  if (sleepState != CAMERA_ASLEEP || !timesyncWakeAt(local_us)) {
    return false;
  }
  // MCLK starts 2 ms before local_us (kernel timer), DPPI sets XSLEEP at local_us. Fixed
  // exposure keeps the sensor awake, so nothing is pending here.
  sleepState = CAMERA_AWAKE;
  wakeAtUs = local_us;
  return true;
}

// Before the MCLK timer (2 ms ahead) with some margin, nothing has happened yet.
#define CAMERA_CANCEL_MARGIN_US 3000

bool cameraCancelWakeAt(void)
{
  if (wakeAtUs == 0 || sleepState != CAMERA_AWAKE || timesyncLocalUs() + CAMERA_CANCEL_MARGIN_US > wakeAtUs) {
    return false;
  }
  timesyncCancelWake();
  if (capture_mclk_running()) {  // the timer fired after all (should not happen with the margin)
    capture_mclk_enable(false);
  }
  sleepState = CAMERA_ASLEEP;
  wakeAtUs = 0;
  return true;
}

void cameraSleepOnFrameBoundary(void)
{
  // XSLEEP low inside the 65 us FVLD-low gap: low anywhere inside a frame makes the next
  // wake one frame slower (QVGA 131 -> 235 ms to the first FVLD). DPPI pulls it low on the
  // FVLD fall; cameraAsleep() then stops MCLK.
  sleepState = CAMERA_FALLING_ASLEEP;
  sleepTimedOut = false;
  wakeAtUs = 0;
  sleepTimeoutMs = capture_xsleep_on_frame_boundary() ? CAMERA_SLEEP_AFTER_FRAME_TIMEOUT_MS
                                                      : CAMERA_SLEEP_ANYTIME_TIMEOUT_MS;
  k_timer_start(&sleepTimeoutTimer, K_MSEC(sleepTimeoutMs), K_NO_WAIT);
}

void cameraAsleep(void)
{
  if (sleepState != CAMERA_FALLING_ASLEEP) {
    return;
  }
  k_timer_stop(&sleepTimeoutTimer);
  nrf_delay_us(CAMERA_XSLEEP_SETTLE_US);
  capture_mclk_enable(false);
  sleepState = CAMERA_ASLEEP;
}

bool cameraWaitAsleep(uint32_t *waited_us)
{
  uint32_t t0 = systemTimeGetUs();
  uint32_t count0 = capture_asleep_count();  // called right after arming: the boundary is ahead
  bool fired = false;
  for (int i = 0; i < 1000 && sleepState == CAMERA_FALLING_ASLEEP && !sleepTimedOut; i++) {
    if (capture_asleep_count() != count0) {
      fired = true;
      break;
    }
    k_busy_wait(200);
  }
  *waited_us = systemTimeGetUs() - t0;
  cameraAsleep();
  return fired;
}

bool cameraIsAsleep(void)
{
  return sleepState == CAMERA_ASLEEP;
}

void cameraArmSlot(uint32_t slot, uint8_t skipFrames)
{
  capture_arm_slot(slot, skipFrames);
}

bool cameraSlotFrame(uint32_t slot, camera_frame_t *frame)
{
  uint8_t *base = cameraInitialized ? frame_pool_slot(slot) : NULL;
  if (base == NULL) {
    return false;
  }
  frame->stride = modeInfo.transport_width;
  frame->width = modeInfo.standard.width;
  frame->height = modeInfo.standard.height;
  frame->pixels = base + (uint32_t)modeInfo.standard.y * frame->stride + modeInfo.standard.x;
  return true;
}
```

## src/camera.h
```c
#ifndef CAMERA_H_
#define CAMERA_H_

#include <stdbool.h>
#include <stdint.h>

/* A frame as sent over BLE: the standard region inside the transport frame. */
typedef struct {
  const uint8_t *pixels;  // first pixel of the standard region
  uint16_t stride;        // transport width
  uint16_t width;
  uint16_t height;
} camera_frame_t;

void cameraInit(void);

void cameraStartStream(void);
void cameraReadyNextFrame(void);
bool cameraGetFrame(camera_frame_t *frame);  // false for a bad frame (wrong DMA byte count / overflow)

/* Monitor (HM0360) */
uint16_t cameraModelId(void);              // 0 until cameraInit() found a sensor
/* R_STATUS camera byte (INTERFACES C2, hub #92): last detection's result, not updated while running. */
#define CAMERA_STATE_UNCHECKED 0  // DK: no picture asked for yet (the camera is initialized lazily)
#define CAMERA_STATE_PRESENT   1  // a sensor answered at 0x24
#define CAMERA_STATE_MISSING   2  // detection ran, nothing answered
uint8_t cameraState(void);
uint16_t cameraProbe(void);                // V3 only: model ID at boot (0: no camera), sensor left in reset
const char *cameraModeName(void);
uint32_t cameraSlotCount(void);            // frame pool slots for the compiled mode
void cameraSensorStream(void);             // MCLK on + sensor streaming, nothing armed
void cameraWake(void);                     // S2 off: MCLK on, then XSLEEP high
bool cameraWakeAt(uint64_t local_us);      // the same at a timesync local time (hardware); false: too late
bool cameraCancelWakeAt(void);             // undo cameraWakeAt() if it is still > 3 ms away (sensor asleep again)
void cameraSleepOnFrameBoundary(void);     // S2 on: XSLEEP low on the next FVLD fall (PPI) ...
void cameraAsleep(void);                   // ... EVENT_CAMERA_ASLEEP: then MCLK off
/* After cameraSleepOnFrameBoundary(): wait here for the boundary (or the timeout), then cameraAsleep().
 * true: on the boundary. The EVENT_CAMERA_ASLEEP that follows does nothing. */
bool cameraWaitAsleep(uint32_t *waited_us);
bool cameraIsAsleep(void);                 // XSLEEP low and MCLK off
void cameraArmSlot(uint32_t slot, uint8_t skipFrames);
bool cameraSlotFrame(uint32_t slot, camera_frame_t *frame);

/* Exposure registers (same addresses on both sensors: 0x0202/0x0203, 0x0205, 0x020E/0x020F). */
typedef struct {
  uint16_t integration;   // rows
  uint8_t analog_gain;
  uint16_t digital_gain;  // 0x020E << 8 | 0x020F
} camera_exposure_t;

bool cameraReadExposure(camera_exposure_t *exposure);  // I2C; false while asleep (S2) or off
/* NULL: automatic exposure (AE). Otherwise AE off and these values (HM0360 only); applied now if
 * the sensor is awake, else right after the next wake. */
void cameraSetExposure(const camera_exposure_t *exposure);
bool cameraExposureManual(void);
void cameraReapplyExposure(void);  // manual and awake: write the fixed values again

#endif
```

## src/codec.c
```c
/* Encoder workspace (codec.h): one block, JPEG state then PNG state, word aligned. */
#include "codec.h"

extern size_t codecJpegStateSize(void);
extern size_t codecPngStateSize(void);

void *codecJpegState;
void *codecPngState;

static size_t align8(size_t n)
{
  return (n + 7) & ~(size_t)7;
}

size_t codecWorkspaceSize(void)
{
  return align8(codecJpegStateSize()) + align8(codecPngStateSize()) + 8;
}

int codecInit(void *workspace, size_t size)
{
  if (workspace == NULL || size < codecWorkspaceSize()) {
    codecJpegState = codecPngState = NULL;
    return -1;
  }
  uintptr_t p = ((uintptr_t)workspace + 7) & ~(uintptr_t)7;
  codecJpegState = (void *)p;
  codecPngState = (void *)(p + align8(codecJpegStateSize()));
  return 0;
}
```

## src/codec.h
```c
/*
 * 8-bit grayscale JPEG / PNG encoders (bitbank2 JPEGENC / PNGenc as C, lib/README.md).
 * Output goes through codec_io_t: sequential writes; PNG also reads back and seeks at the
 * end (chunk length and CRC), so the sink must be random access (PSRAM or RAM).
 * The encoders' state lives in caller-provided memory (codecInit), not in .bss.
 */
#ifndef CODEC_H_
#define CODEC_H_

#include <stddef.h>
#include <stdint.h>

typedef struct codec_io {
  int32_t (*write)(struct codec_io *io, const uint8_t *data, int32_t len);  // at the position; returns len
  int32_t (*read)(struct codec_io *io, uint8_t *data, int32_t len);         // at the position; returns len
  int32_t (*seek)(struct codec_io *io, int32_t position);                   // returns position
  void *ctx;
} codec_io_t;

size_t codecWorkspaceSize(void);
int codecInit(void *workspace, size_t size);  // 0, or -1 if too small

/* Return the encoded size in bytes, or a negative error. quality 1..100 (libjpeg scale). */
int32_t codecJpeg(const uint8_t *pixels, int stride, int width, int height, int quality, codec_io_t *io);
/* Same, pixels from rows(ctx, y, band): 8 rows y..y+7 into band (width x 8, stride width). */
int32_t codecJpegBands(int width, int height, int quality, codec_io_t *io, int (*rows)(void *ctx, int y, uint8_t *band),
                       void *ctx, uint8_t *band);
/* level 0..9 (zlib) */
int32_t codecPng(const uint8_t *pixels, int stride, int width, int height, int level, codec_io_t *io);

#endif
```

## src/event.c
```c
#include <zephyr/kernel.h>
#include <zephyr/sys/printk.h>

#include "event.h"

#define EVENT_QUEUE_DEPTH 100

K_MSGQ_DEFINE(eventQueue, sizeof(event_t), EVENT_QUEUE_DEPTH, 4);

void eventQueuePush(event_t event)
{
  if (k_msgq_put(&eventQueue, &event, K_NO_WAIT) != 0) {
    printk("[event] queue full, dropped %d\n", event);
  }
}

event_t eventQueueWait(void)
{
  event_t event = EVENT_NONE;
  k_msgq_get(&eventQueue, &event, K_FOREVER);
  return event;
}
```
